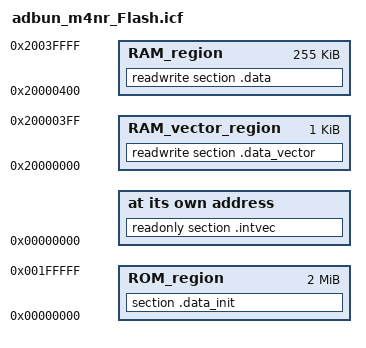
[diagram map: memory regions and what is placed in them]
/*###ICF### Section handled by ICF editor, don't touch! ****/
/*-Editor annotation file-*/
/* IcfEditorFile="$TOOLKIT_DIR$\config\ide\IcfEditor\a_v1_0.xml" */
/*-Specials-*/
define symbol __ICFEDIT_intvec_start__ = 0x00000000;
/*-Memory Regions-*/
define symbol __ICFEDIT_region_ROM_start__ = 0x00000000;
define symbol __ICFEDIT_region_ROM_end__   = 0x001FFFFF;
define symbol __ICFEDIT_region_RAM_start__ = 0x20000400;
define symbol __ICFEDIT_region_RAM_end__   = 0x2003FFFF;

define symbol __region_RAM_vector_start__ = 0x20000000;
define symbol __region_RAM_vector_end__   = 0x200003FF;

/*-Sizes-*/
define symbol __ICFEDIT_size_cstack__ = 0x1000;
define symbol __ICFEDIT_size_heap__   = 0x1000;
/**** End of ICF editor section. ###ICF###*/

define symbol __code_start__ = 0x00000400;

define memory mem with size = 4G;
define region ROM_region   = mem:[from __ICFEDIT_region_ROM_start__   to __ICFEDIT_region_ROM_end__];
define region RAM_region   = mem:[from __ICFEDIT_region_RAM_start__   to __ICFEDIT_region_RAM_end__];
define region RAM_vector_region   = mem:[from __region_RAM_vector_start__   to __region_RAM_vector_end__];


define block CSTACK    with alignment = 8, size = __ICFEDIT_size_cstack__   { };
define block HEAP      with alignment = 8, size = __ICFEDIT_size_heap__     { };

initialize manually { readwrite };
do not initialize  { section .noinit };
do not initialize  { readwrite };

place at address mem:__ICFEDIT_intvec_start__ { readonly section .intvec };

place at address mem:__code_start__  {
	readonly,
	block .text {
		section .ftext.1,
		section .romtext.1,
		section .ftext.2,
		section .romtext.2,
		section .ftext.3,
		section .text,
		section .rodata,
		section .rodata.*,
	},
};

place in ROM_region   { section .data_init };
place in RAM_region   { readwrite section .data};
place in RAM_region {
	readwrite,
	block .bss {
		section .noinit,
		section .bss,
		section COMMON
	},
	block CSTACK,
	block HEAP
};

place in RAM_vector_region   {
	readwrite section .data_vector
};
